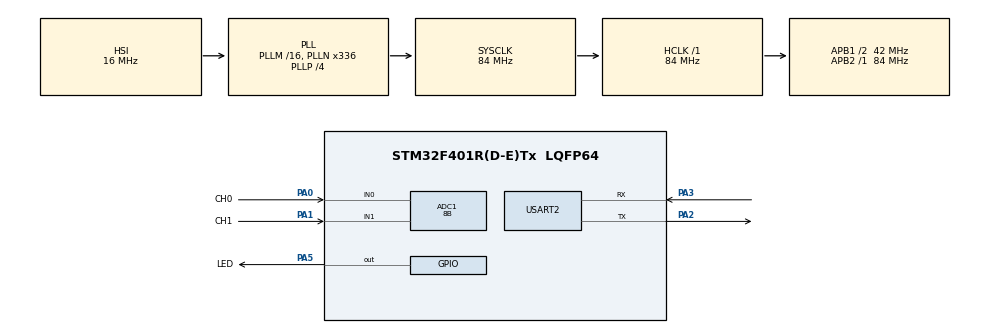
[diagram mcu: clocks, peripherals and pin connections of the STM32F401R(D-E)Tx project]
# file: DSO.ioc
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ADC1.Channel-0\#ChannelRegularConversion=ADC_CHANNEL_0
ADC1.Channel-4\#ChannelInjectedConversion=ADC_CHANNEL_1
ADC1.ContinuousConvMode=DISABLE
ADC1.DMAContinuousRequests=DISABLE
ADC1.DiscontinuousConvMode=DISABLE
ADC1.EnableAnalogWatchDog=false
ADC1.ExternalTrigConv=ADC_EXTERNALTRIGCONV_T3_TRGO
ADC1.InjNumberOfConversion=1
ADC1.InjectedConvMode=AutoInjected
ADC1.InjectedOffset-4\#ChannelInjectedConversion=0
ADC1.InjectedRank-4\#ChannelInjectedConversion=1
ADC1.NbrOfConversion=1
ADC1.NbrOfConversionFlag=1
ADC1.Rank-0\#ChannelRegularConversion=1
ADC1.Resolution=ADC_RESOLUTION_8B
ADC1.SamplingTime-0\#ChannelRegularConversion=ADC_SAMPLETIME_3CYCLES
ADC1.SamplingTime-4\#ChannelInjectedConversion=ADC_SAMPLETIME_3CYCLES
ADC1.ScanConvMode=DISABLE
ADC1.master=1
Mcu.Family=STM32F4
Mcu.Name=STM32F401R(D-E)Tx
Mcu.Package=LQFP64
NVIC.ADC_IRQn=true\:0\:0\:true\:false\:true\:true\:true
NVIC.PriorityGroup=NVIC_PRIORITYGROUP_4
NVIC.USART2_IRQn=true\:10\:0\:true\:false\:true\:true\:true
PA0-WKUP.GPIO_Label=CH0
PA0-WKUP.Signal=ADCx_IN0
PA1.GPIO_Label=CH1
PA1.Signal=ADCx_IN1
PA2.Mode=Asynchronous
PA2.Signal=USART2_TX
PA3.Mode=Asynchronous
PA3.Signal=USART2_RX
PA5.GPIO_Label=LED
PA5.Signal=GPIO_Output
ProjectManager.HeapSize=0x200
ProjectManager.StackSize=0x400
ProjectManager.TargetToolchain=STM32CubeIDE
RCC.48MHZClocksFreq_Value=84000000
RCC.AHBFreq_Value=84000000
RCC.APB1CLKDivider=RCC_HCLK_DIV2
RCC.APB1Freq_Value=42000000
RCC.APB1TimFreq_Value=84000000
RCC.APB2Freq_Value=84000000
RCC.APB2TimFreq_Value=84000000
RCC.CortexFreq_Value=84000000
RCC.HCLKFreq_Value=84000000
RCC.HSE_VALUE=25000000
RCC.HSI_VALUE=16000000
RCC.LSE_VALUE=32768
RCC.PLLN=336
RCC.PLLP=RCC_PLLP_DIV4
RCC.SYSCLKFreq_VALUE=84000000
RCC.SYSCLKSource=RCC_SYSCLKSOURCE_PLLCLK
RCC.VCOOutputFreq_Value=336000000
SH.ADCx_IN0.0=ADC1_IN0,IN0
SH.ADCx_IN1.0=ADC1_IN1,IN1
TIM3.AutoReloadPreload=TIM_AUTORELOAD_PRELOAD_DISABLE
TIM3.Channel-Output\ Compare1\ No\ Output=TIM_CHANNEL_1
TIM3.Period=500
TIM3.Prescaler=168
TIM3.TIM_MasterOutputTrigger=TIM_TRGO_UPDATE
USART2.VirtualMode=VM_ASYNC
VP_TIM3_VS_ClockSourceINT.Mode=Internal
VP_TIM3_VS_no_output1.Mode=Output Compare1 No Output
board=custom

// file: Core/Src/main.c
/* USER CODE BEGIN Header */
/**
  ******************************************************************************
  * @file           : main.c
  * @brief          : Main program body
  ******************************************************************************
  * @attention
  *
  * <h2><center>&copy; Copyright (c) 2021 STMicroelectronics.
  * All rights reserved.</center></h2>
  *
  * This software component is licensed by ST under BSD 3-Clause license,
  * the "License"; You may not use this file except in compliance with the
  * License. You may obtain a copy of the License at:
  *                        opensource.org/licenses/BSD-3-Clause
  *
  ******************************************************************************
  */
/* USER CODE END Header */
#include "main.h"

/* USER CODE BEGIN Includes */
#include "DSO_application.h"
/* USER CODE END Includes */

ADC_HandleTypeDef hadc1;

TIM_HandleTypeDef htim3;

UART_HandleTypeDef huart2;

void SystemClock_Config(void);
static void MX_GPIO_Init(void);
static void MX_ADC1_Init(void);
static void MX_TIM3_Init(void);
static void MX_USART2_UART_Init(void);

int main(void)
{

  /* MCU Configuration--------------------------------------------------------*/

  /* Reset of all peripherals, Initializes the Flash interface and the Systick. */
  HAL_Init();

  /* Configure the system clock */
  SystemClock_Config();

  /* Initialize all configured peripherals */
  MX_GPIO_Init();
  MX_ADC1_Init();
  MX_TIM3_Init();
  MX_USART2_UART_Init();

  /* Infinite loop */
  /* USER CODE BEGIN WHILE */

  if (HAL_ADC_Start_IT(&hadc1) != HAL_OK)    // Accensione ADC
  {
 	Error_Handler();
  }
  if (HAL_ADCEx_InjectedStart_IT(&hadc1) != HAL_OK)    // Accensione ADC injected mode
  {
   	Error_Handler();
  }
  if (HAL_TIM_OC_Start_IT(&htim3, TIM_CHANNEL_1) != HAL_OK)    // Accensione TIMER
  {
    Error_Handler();
  }
  DSO_StartRX();   // Inizio ricezione comandi da seriale

  while (1)
  {
	DSO_UserCode();
    /* USER CODE END WHILE */

  }
}

void SystemClock_Config(void)
{
  RCC_OscInitTypeDef RCC_OscInitStruct = {0};
  RCC_ClkInitTypeDef RCC_ClkInitStruct = {0};

  /** Configure the main internal regulator output voltage
  */
  __HAL_RCC_PWR_CLK_ENABLE();
  __HAL_PWR_VOLTAGESCALING_CONFIG(PWR_REGULATOR_VOLTAGE_SCALE2);
  /** Initializes the RCC Oscillators according to the specified parameters
  * in the RCC_OscInitTypeDef structure.
  */
  RCC_OscInitStruct.OscillatorType = RCC_OSCILLATORTYPE_HSI;
  RCC_OscInitStruct.HSIState = RCC_HSI_ON;
  RCC_OscInitStruct.HSICalibrationValue = RCC_HSICALIBRATION_DEFAULT;
  RCC_OscInitStruct.PLL.PLLState = RCC_PLL_ON;
  RCC_OscInitStruct.PLL.PLLSource = RCC_PLLSOURCE_HSI;
  RCC_OscInitStruct.PLL.PLLM = 16;
  RCC_OscInitStruct.PLL.PLLN = 336;
  RCC_OscInitStruct.PLL.PLLP = RCC_PLLP_DIV4;
  RCC_OscInitStruct.PLL.PLLQ = 4;
  if (HAL_RCC_OscConfig(&RCC_OscInitStruct) != HAL_OK)
  {
    Error_Handler();
  }
  /** Initializes the CPU, AHB and APB buses clocks
  */
  RCC_ClkInitStruct.ClockType = RCC_CLOCKTYPE_HCLK|RCC_CLOCKTYPE_SYSCLK
                              |RCC_CLOCKTYPE_PCLK1|RCC_CLOCKTYPE_PCLK2;
  RCC_ClkInitStruct.SYSCLKSource = RCC_SYSCLKSOURCE_PLLCLK;
  RCC_ClkInitStruct.AHBCLKDivider = RCC_SYSCLK_DIV1;
  RCC_ClkInitStruct.APB1CLKDivider = RCC_HCLK_DIV2;
  RCC_ClkInitStruct.APB2CLKDivider = RCC_HCLK_DIV1;

  if (HAL_RCC_ClockConfig(&RCC_ClkInitStruct, FLASH_LATENCY_2) != HAL_OK)
  {
    Error_Handler();
  }
}

static void MX_ADC1_Init(void)
{

  ADC_ChannelConfTypeDef sConfig = {0};
  ADC_InjectionConfTypeDef sConfigInjected = {0};

  /** Configure the global features of the ADC (Clock, Resolution, Data Alignment and number of conversion)
  */
  hadc1.Instance = ADC1;
  hadc1.Init.ClockPrescaler = ADC_CLOCK_SYNC_PCLK_DIV4;
  hadc1.Init.Resolution = ADC_RESOLUTION_8B;
  hadc1.Init.ScanConvMode = DISABLE;
  hadc1.Init.ContinuousConvMode = DISABLE;
  hadc1.Init.DiscontinuousConvMode = DISABLE;
  hadc1.Init.ExternalTrigConvEdge = ADC_EXTERNALTRIGCONVEDGE_RISING;
  hadc1.Init.ExternalTrigConv = ADC_EXTERNALTRIGCONV_T3_TRGO;
  hadc1.Init.DataAlign = ADC_DATAALIGN_RIGHT;
  hadc1.Init.NbrOfConversion = 1;
  hadc1.Init.DMAContinuousRequests = DISABLE;
  hadc1.Init.EOCSelection = ADC_EOC_SINGLE_CONV;
  if (HAL_ADC_Init(&hadc1) != HAL_OK)
  {
    Error_Handler();
  }
  /** Configure for the selected ADC regular channel its corresponding rank in the sequencer and its sample time.
  */
  sConfig.Channel = ADC_CHANNEL_0;
  sConfig.Rank = 1;
  sConfig.SamplingTime = ADC_SAMPLETIME_3CYCLES;
  if (HAL_ADC_ConfigChannel(&hadc1, &sConfig) != HAL_OK)
  {
    Error_Handler();
  }
  /** Configures for the selected ADC injected channel its corresponding rank in the sequencer and its sample time
  */
  sConfigInjected.InjectedChannel = ADC_CHANNEL_1;
  sConfigInjected.InjectedRank = 1;
  sConfigInjected.InjectedNbrOfConversion = 1;
  sConfigInjected.InjectedSamplingTime = ADC_SAMPLETIME_3CYCLES;
  sConfigInjected.ExternalTrigInjecConvEdge = ADC_EXTERNALTRIGINJECCONVEDGE_NONE;
  sConfigInjected.ExternalTrigInjecConv = ADC_INJECTED_SOFTWARE_START;
  sConfigInjected.AutoInjectedConv = ENABLE;
  sConfigInjected.InjectedDiscontinuousConvMode = DISABLE;
  sConfigInjected.InjectedOffset = 0;
  if (HAL_ADCEx_InjectedConfigChannel(&hadc1, &sConfigInjected) != HAL_OK)
  {
    Error_Handler();
  }

}

static void MX_TIM3_Init(void)
{

  TIM_ClockConfigTypeDef sClockSourceConfig = {0};
  TIM_MasterConfigTypeDef sMasterConfig = {0};
  TIM_OC_InitTypeDef sConfigOC = {0};

  htim3.Instance = TIM3;
  htim3.Init.Prescaler = 168;
  htim3.Init.CounterMode = TIM_COUNTERMODE_UP;
  htim3.Init.Period = 500;
  htim3.Init.ClockDivision = TIM_CLOCKDIVISION_DIV1;
  htim3.Init.AutoReloadPreload = TIM_AUTORELOAD_PRELOAD_DISABLE;
  if (HAL_TIM_Base_Init(&htim3) != HAL_OK)
  {
    Error_Handler();
  }
  sClockSourceConfig.ClockSource = TIM_CLOCKSOURCE_INTERNAL;
  if (HAL_TIM_ConfigClockSource(&htim3, &sClockSourceConfig) != HAL_OK)
  {
    Error_Handler();
  }
  if (HAL_TIM_OC_Init(&htim3) != HAL_OK)
  {
    Error_Handler();
  }
  sMasterConfig.MasterOutputTrigger = TIM_TRGO_UPDATE;
  sMasterConfig.MasterSlaveMode = TIM_MASTERSLAVEMODE_DISABLE;
  if (HAL_TIMEx_MasterConfigSynchronization(&htim3, &sMasterConfig) != HAL_OK)
  {
    Error_Handler();
  }
  sConfigOC.OCMode = TIM_OCMODE_TIMING;
  sConfigOC.Pulse = 0;
  sConfigOC.OCPolarity = TIM_OCPOLARITY_HIGH;
  sConfigOC.OCFastMode = TIM_OCFAST_DISABLE;
  if (HAL_TIM_OC_ConfigChannel(&htim3, &sConfigOC, TIM_CHANNEL_1) != HAL_OK)
  {
    Error_Handler();
  }

}

static void MX_USART2_UART_Init(void)
{

  huart2.Instance = USART2;
  huart2.Init.BaudRate = 115200;
  huart2.Init.WordLength = UART_WORDLENGTH_8B;
  huart2.Init.StopBits = UART_STOPBITS_1;
  huart2.Init.Parity = UART_PARITY_NONE;
  huart2.Init.Mode = UART_MODE_TX_RX;
  huart2.Init.HwFlowCtl = UART_HWCONTROL_NONE;
  huart2.Init.OverSampling = UART_OVERSAMPLING_16;
  if (HAL_UART_Init(&huart2) != HAL_OK)
  {
    Error_Handler();
  }

}

static void MX_GPIO_Init(void)
{
  GPIO_InitTypeDef GPIO_InitStruct = {0};

  /* GPIO Ports Clock Enable */
  __HAL_RCC_GPIOA_CLK_ENABLE();

  /*Configure GPIO pin Output Level */
  HAL_GPIO_WritePin(LED_GPIO_Port, LED_Pin, GPIO_PIN_RESET);

  /*Configure GPIO pin : LED_Pin */
  GPIO_InitStruct.Pin = LED_Pin;
  GPIO_InitStruct.Mode = GPIO_MODE_OUTPUT_PP;
  GPIO_InitStruct.Pull = GPIO_NOPULL;
  GPIO_InitStruct.Speed = GPIO_SPEED_FREQ_LOW;
  HAL_GPIO_Init(LED_GPIO_Port, &GPIO_InitStruct);

}

void Error_Handler(void)
{
  /* USER CODE BEGIN Error_Handler_Debug */
  /* User can add his own implementation to report the HAL error return state */

  // Manteniamo il LED acceso per segnalare un errore:
  HAL_GPIO_WritePin (LED_GPIO_Port, LED_Pin, GPIO_PIN_SET);
  while(1);

  /* USER CODE END Error_Handler_Debug */
}

/************************ (C) COPYRIGHT STMicroelectronics *****END OF FILE****/
